# A31L12x register map
Vendor: VENDOR ABOV Semiconductor Co., Ltd.; Series: A31L12x; File version: 1.0
CPU: CM0+ r0p1, little endian, no MPU, no FPU, VTOR, 2 interrupt priority bits
Registers are 32-bit, read-write, reset 0x0 unless marked. A register's access mark holds for its fields unless they carry their own. Offsets are from the block's base; [hi:lo] are bit positions; {n}, {i} and the like mark numbered series.

## CRC — Cyclic Redundancy Check and Checksum
Base 0x30001000
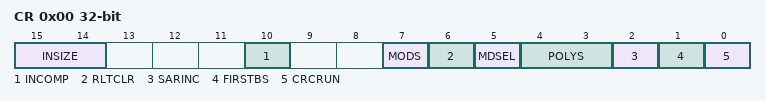
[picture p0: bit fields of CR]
0x00 CR — CRC/Checksum Control Register
  [15:14] INSIZE — Input Data Size Selection
    0=32-bit is the input data size; 1=16-bit is the input data size; 2=8-bit is the input data size
  [10] INCOMP — Input Data Complement
    0=Disable (No effect.); 1=Enable (1's complement of input data)
  [7] MODS — User/Auto Mode Selection
    0=User Mode (Calculate every data written to the CRC_IN register); 1=Auto Mode (Calculate till CRC_SADR == CRC_EADR)
  [6] RLTCLR — CRC/Checksum Result Data Register (CRC_RLT) Initialization
    0=NoEffect; 1=Initialize the CRC_RLT register with the value of CRC_INIT. (This bit is automatically cleared to '0' after operation.)
  [5] MDSEL — CRC/Checksum Selection
    0=CRC (Select CRC.); 1=Checksum (Select Checksum.)
  [4:3] POLYS — Polynomial Selection (CRC only)
    0=CRC16_CCITT (CRC16-CCITT (G1(x) = x16 + x12 + x5 + 1)); 1=CRC16 (CRC16 (G2(x) = x16 + x15 + x2 + 1)); 2=CRC8 (CRC8 (G3(x) = x8 + x2 + x + 1)); 3=CRC32 (CRC32 (G4(x) = x32 + x26 + x23 + x22 + x16 + x12 + x11 + x10 +x8 + x7 + x5 + x4 + x2 + x + 1))
  [2] SARINC — CRC/Checksum Start Address Auto Increment Control (User mode only)
    0=Disable (No effect.); 1=Enable (The CRC/Checksum start address register is incremented as the selected input size every writing to the CRC_IN register.)
  [1] FIRSTBS — First Shifted-in Selection (CRC only)
    0=msbFirst; 1=lsbFirst
  [0] CRCRUN — CRC/Checksum Start/Stop Control
    0=Stop (Not busy. The CRC operation can be finished by writing '0' to this bit while running.); 1=Start CRC operation. This bit is automatically cleared to '0' when the value of CRC_SADR register reaches the value of CRC_EADR register.
0x04 IN — CRC/Checksum Input Data Register
  [31:0] INDATA — CRC Input Data
0x08 RLT ro reset 0xFFFFFFFF — CRC/Checksum Result Data Register
  [31:0] RLTDATA — CRC Result Data
0x0C INIT — CRC/Checksum Initial Data Register
  [31:0] INIDATA — CRC Initial Data
0x10 SADR reset 0x10000000 — CRC/Checksum Start Address Register
  [31:0] SADR — CRC Start Address
0x14 EADR reset 0x1000FFFF — CRC/Checksum End Address Register
  [31:0] EADR — CRC End Address

## DMACn — DMA Controller Channel n
Base 0x59000000
Same registers: DMAC0 0x40005D00, DMAC1 0x40005D20, DMAC2 0x40005D40, DMAC3 0x40005D60, DMAC4 0x40005D80
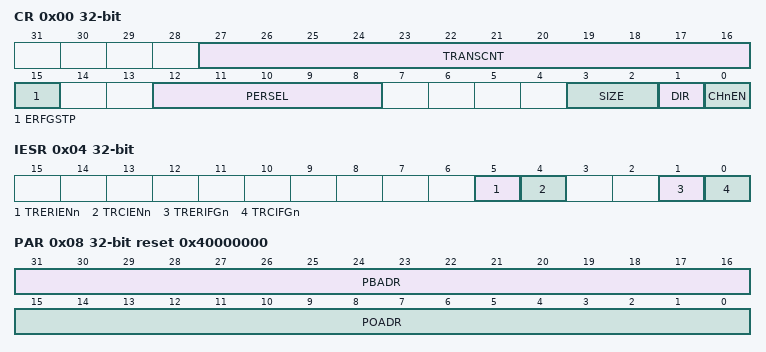
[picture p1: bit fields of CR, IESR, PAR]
0x00 CR — DMA Channel n Control Register
  [27:16] TRANSCNT — The number of times to transfer
  [15] ERFGSTP — Error Flag Stop
    0=Disable DMA stop function by an error of peripheral; 1=Enable DMA stop function by an error of peripheral
  [12:8] PERSEL — Peripheral Selection
    0=Idle (Channel idle); 1=ADC (ADC Output); 2=SPI0Rx; 3=SPI0Tx; 4=SPI1Rx; 5=SPI1Tx; 6=USART10Rx; 7=USART10Tx; 8=I2C0Rx; 9=I2C0Tx; 10=I2C1Rx; 11=I2C1Tx; 12=UART0Rx; 13=UART0Tx; 14=UART1Rx; 15=UART1Tx; 16=LPUARTRx; 17=LPUARTTx; 18=SC0Rx; 19=SC0Tx; 20=SC1Rx; 21=SC1Tx
  [3:2] SIZE — Transfer Size Selection
    0=8 bits; 1=16 bits; 2=32 bits
  [1] DIR — Transfer Direction
    0=MemToPeri (Transfer is from memory to peripheral.); 1=PeriToMem (Transfer is from peripheral to memory.)
  [0] CHnEN — DMA Channel Enable
    0=Disable channel n; 1=Enable channel n
0x04 IESR — DMA Channel n Interrupt Enable and Status Register
  [5] TRERIENn — Transfer Error Interrupt Enable
    0=Disable transfer error interrupt; 1=Enable transfer error interrupt
  [4] TRCIENn — Transfer Complete Interrupt Enable
    0=Disable transfer complete interrupt; 1=Enable transfer complete interrupt
  [1] TRERIFGn — Transfer Error Interrupt Flag
    0=No request occurred; 1=Request occurred
  [0] TRCIFGn — Transfer Complete Interrupt Flag
    0=No request occurred; 1=Request occurred
0x08 PAR reset 0x40000000 — DMA Channel n Peripheral Address Register
  [31:16] PBADR — Peripheral Base Address
  [15:0] POADR — Peripheral Offset Address
0x0C MAR reset 0x20000000 — DMA Channel n Memory Address Register
  [31:0] MAR — Memory Address

## COA0 — Configuration Option Area Page 0: System Related Trimming Value
Base 0x1FFFF000
{0x0+4i} TRIM{i:02} ro reset not defined (i=0..19) — System Related Trim Value {i:02}
0x50 CONF_MF1CNFIG ro reset not defined — Manufacture Information 1
  [31:0] XYCDN — X and Y Coordinates
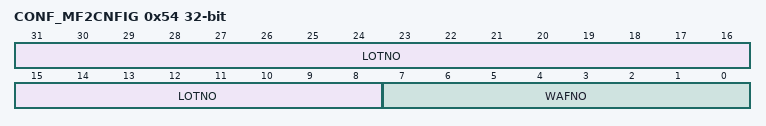
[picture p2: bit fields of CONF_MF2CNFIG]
0x54 CONF_MF2CNFIG ro reset not defined — Manufacture Information 2
  [31:8] LOTNO — Lot Number [23:0]
  [7:0] WAFNO — Wafer Number
0x58 CONF_MF3CNFIG ro reset not defined — Manufacture Information 3
  [31:0] LOTNO — Lot Number [55:24]
0x5C CONF_MF4CNFIG ro reset not defined — Manufacture Information 4
  [31:0] LOTNO — Lot Number [87:56]
{0x0+4i} TRIM{i} ro reset not defined (i=24..31) — System Related Trim Value {i}

## COA1 — Configuration Option Area Page 1: User Option
Base 0x1FFFF200
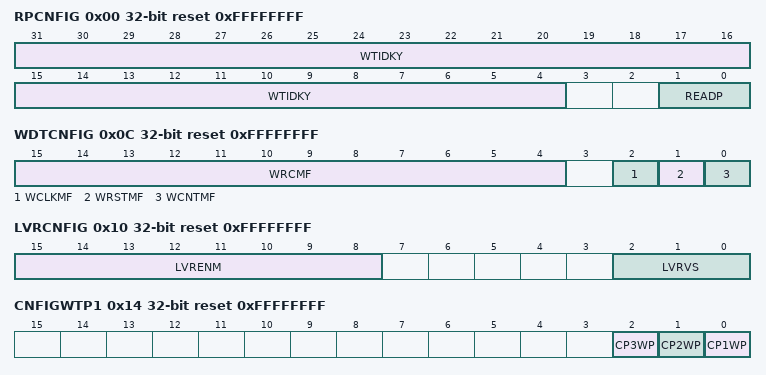
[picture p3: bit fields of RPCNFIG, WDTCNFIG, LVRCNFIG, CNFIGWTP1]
0x00 RPCNFIG ro reset 0xFFFFFFFF (reset mask 0xFFFFFFFC) — Configuration for Read Protection
  [31:4] WTIDKY — Write Identification Key (0x69c8a27)
    0x69C8A27=Value (Key Value (0x69c8a27))
  [1:0] READP — Read Protection for Flash Memory Area
    3=Level0 (No restriction for read/erase/write.); 2=Level1 (1. Not readable/erasable/writable by 'Debug' 2. Bulk erasable only by 'Debug' 3. Readable/erasable/writable by 'Instruction from Flash Memory and RAM'); 0=Level2 (1. Not readable/erasable/writable by 'Debug' / 'Instruction from RAM' 2. Bulk erasable only by 'Instruction from RAM' / 'Debug' 3. Readable/erasable/writable by 'Instruction from Flash Memory')
0x0C WDTCNFIG ro reset 0xFFFFFFFF (reset mask 0xFFFF0008) — Configuration for Watch-Dog Timer
  [15:4] WRCMF — Watch-Dog Timer RC Oscillator Master Configuration
    0x96D=By S/W (CLKSRCR Register) (0x96d); 0x2A7=AlwaysEnableExceptDeepSleep (Always Enable Except for Deep Sleep (0x2a7)); 0xFFF=AlwaysEnable
  [2] WCLKMF — Watch-Dog Timer Clock Selection Master Configuration
    0=By S/W (PPCLKSR Register); 1=AlwaysWDTRC
  [1] WRSTMF — Watch-Dog Timer Reset Enable Master Configuration
    0=AlwaysEnable; 1=By S/W (WDTCR Register)
  [0] WCNTMF — Watch-Dog Timer Counter Enable Master Configuration
    0=AlwaysEnable; 1=By S/W (WDTCR Register)
0x10 LVRCNFIG ro reset 0xFFFFFFFF (reset mask 0xFFFF00F8) — Configuration for Low Voltage Reset
  [15:8] LVRENM — LVR Reset Operation Control Master Configuration
    170=By S/W (LVRCR Register) (0xaa); 255=Always Enable (0xff)
  [2:0] LVRVS — LVR Voltage Selection
    7=1p50V (1.50V); 6=1p75V (1.75V); 5=1p90V (1.90V); 4=2p05V (2.05V); 3=2p20V (2.20V); 2=2p35V (2.35V); 1=2p50V (2.50V); 0=2p65V (2.65V)
0x14 CNFIGWTP1 ro reset 0xFFFFFFFF (reset mask 0xFFFFFFF8) — Erase/Write Protection for Configure Option Page 1/2/3
  [all] fields
    0=Enable protection. (Not erasable/writable by instruction); 1=Disable protection. (Erasable/writable by instruction)
  [2] CP3WP — Configure Option Page 3 Erase/Write Protection
  [1] CP2WP — Configure Option Page 2 Erase/Write Protection
  [0] CP1WP — Configure Option Page 1 Erase/Write Protection
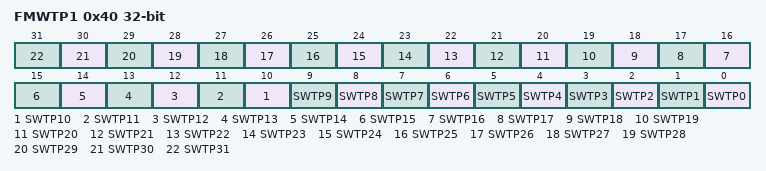
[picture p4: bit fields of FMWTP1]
0x40 FMWTP1 ro reset not defined — Erase/Write Protection for Flash Memory
  [all] fields
    0=Enable (Protect 'flash memory sector n erase/write'); 1=Disable (Permit 'flash memory sector n erase/write')
  [n] SWTP{n} (n=0..31) — Flash Memory Erase/Write Protection {n}

## COA2 — Configuration Option Area Page 2: User Data Area 0
Base 0x1FFFF400
Same registers: COA3 0x1FFFF600
{0x0+4i} UDATA{i:02} ro reset not defined (i=0..31) — User Data {i:02}
